[part 2 of 2: packages /PATAC/MSM/ModeAdjust to /PATAC/MSM/PortInterfaces]
AUTOSAR XML (schema 4-0-3)
package /PATAC/MSM/ModeAdjust
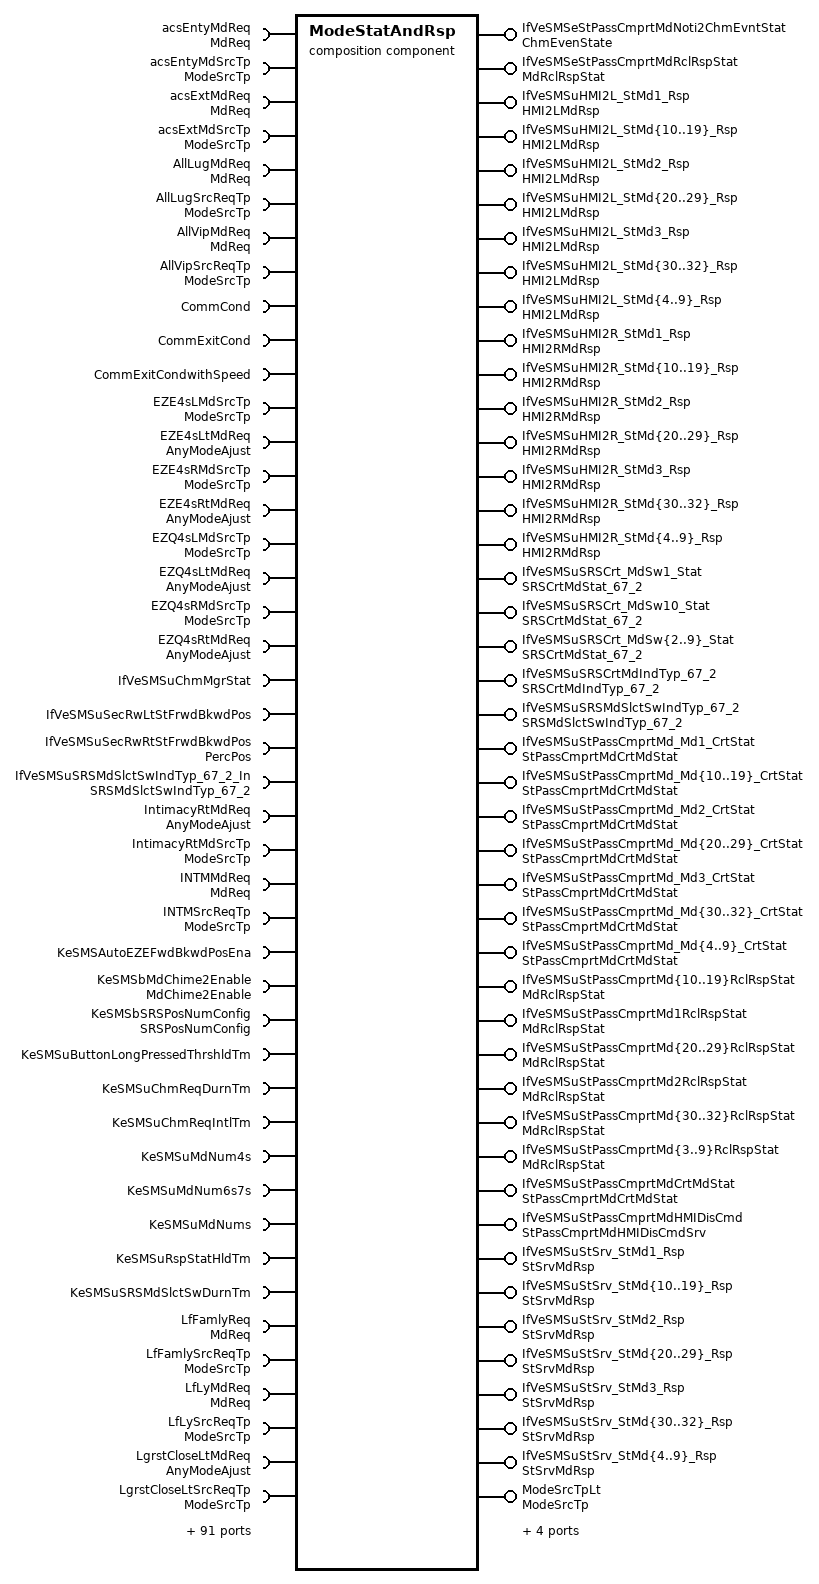
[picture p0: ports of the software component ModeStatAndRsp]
  composition sw component type ModeStatAndRsp
    181 x provide port:
      IfVeSMSeStPassCmprtMdNoti2ChmEvntStat: nonqueued-sender-com-spec=data-element=ChmEvenState/Val, provided-interface=ChmEvenState
      IfVeSMSeStPassCmprtMdRclRspStat: nonqueued-sender-com-spec=data-element=MdRclRspStat/Val, provided-interface=MdRclRspStat
      IfVeSMSuHMI2L_StMd1_Rsp: nonqueued-sender-com-spec=data-element=HMI2LMdRsp/Val, provided-interface=HMI2LMdRsp
      IfVeSMSuHMI2L_StMd{10..19}_Rsp: nonqueued-sender-com-spec=data-element=HMI2LMdRsp/Val, provided-interface=HMI2LMdRsp
      IfVeSMSuHMI2L_StMd2_Rsp: nonqueued-sender-com-spec=data-element=HMI2LMdRsp/Val, provided-interface=HMI2LMdRsp
      IfVeSMSuHMI2L_StMd{20..29}_Rsp: nonqueued-sender-com-spec=data-element=HMI2LMdRsp/Val, provided-interface=HMI2LMdRsp
      IfVeSMSuHMI2L_StMd3_Rsp: nonqueued-sender-com-spec=data-element=HMI2LMdRsp/Val, provided-interface=HMI2LMdRsp
      IfVeSMSuHMI2L_StMd{30..32}_Rsp: nonqueued-sender-com-spec=data-element=HMI2LMdRsp/Val, provided-interface=HMI2LMdRsp
      IfVeSMSuHMI2L_StMd{4..9}_Rsp: nonqueued-sender-com-spec=data-element=HMI2LMdRsp/Val, provided-interface=HMI2LMdRsp
      IfVeSMSuHMI2R_StMd1_Rsp: nonqueued-sender-com-spec=data-element=HMI2RMdRsp/Val, provided-interface=HMI2RMdRsp
      IfVeSMSuHMI2R_StMd{10..19}_Rsp: nonqueued-sender-com-spec=data-element=HMI2RMdRsp/Val, provided-interface=HMI2RMdRsp
      IfVeSMSuHMI2R_StMd2_Rsp: nonqueued-sender-com-spec=data-element=HMI2RMdRsp/Val, provided-interface=HMI2RMdRsp
      IfVeSMSuHMI2R_StMd{20..29}_Rsp: nonqueued-sender-com-spec=data-element=HMI2RMdRsp/Val, provided-interface=HMI2RMdRsp
      IfVeSMSuHMI2R_StMd3_Rsp: nonqueued-sender-com-spec=data-element=HMI2RMdRsp/Val, provided-interface=HMI2RMdRsp
      IfVeSMSuHMI2R_StMd{30..32}_Rsp: nonqueued-sender-com-spec=data-element=HMI2RMdRsp/Val, provided-interface=HMI2RMdRsp
      IfVeSMSuHMI2R_StMd{4..9}_Rsp: nonqueued-sender-com-spec=data-element=HMI2RMdRsp/Val, provided-interface=HMI2RMdRsp
      IfVeSMSuSRSCrt_MdSw1_Stat: nonqueued-sender-com-spec=data-element=SRSCrtMdStat_67_2/Val, provided-interface=SRSCrtMdStat_67_2
      IfVeSMSuSRSCrt_MdSw10_Stat: nonqueued-sender-com-spec=data-element=SRSCrtMdStat_67_2/Val, provided-interface=SRSCrtMdStat_67_2
      IfVeSMSuSRSCrt_MdSw{2..9}_Stat: nonqueued-sender-com-spec=data-element=SRSCrtMdStat_67_2/Val, provided-interface=SRSCrtMdStat_67_2
      IfVeSMSuSRSCrtMdIndTyp_67_2: nonqueued-sender-com-spec=data-element=SRSCrtMdIndTyp_67_2/Val, provided-interface=SRSCrtMdIndTyp_67_2
      IfVeSMSuSRSMdSlctSwIndTyp_67_2: nonqueued-sender-com-spec{data-element=SRSMdSlctSwIndTyp_67_2/Val, init-value=1}, provided-interface=SRSMdSlctSwIndTyp_67_2
      IfVeSMSuStPassCmprtMd_Md1_CrtStat: nonqueued-sender-com-spec=data-element=StPassCmprtMdCrtMdStat/Val, provided-interface=StPassCmprtMdCrtMdStat
      IfVeSMSuStPassCmprtMd_Md{10..19}_CrtStat: nonqueued-sender-com-spec=data-element=StPassCmprtMdCrtMdStat/Val, provided-interface=StPassCmprtMdCrtMdStat
      IfVeSMSuStPassCmprtMd_Md2_CrtStat: nonqueued-sender-com-spec=data-element=StPassCmprtMdCrtMdStat/Val, provided-interface=StPassCmprtMdCrtMdStat
      IfVeSMSuStPassCmprtMd_Md{20..29}_CrtStat: nonqueued-sender-com-spec=data-element=StPassCmprtMdCrtMdStat/Val, provided-interface=StPassCmprtMdCrtMdStat
      IfVeSMSuStPassCmprtMd_Md3_CrtStat: nonqueued-sender-com-spec=data-element=StPassCmprtMdCrtMdStat/Val, provided-interface=StPassCmprtMdCrtMdStat
      IfVeSMSuStPassCmprtMd_Md{30..32}_CrtStat: nonqueued-sender-com-spec=data-element=StPassCmprtMdCrtMdStat/Val, provided-interface=StPassCmprtMdCrtMdStat
      IfVeSMSuStPassCmprtMd_Md{4..9}_CrtStat: nonqueued-sender-com-spec=data-element=StPassCmprtMdCrtMdStat/Val, provided-interface=StPassCmprtMdCrtMdStat
      IfVeSMSuStPassCmprtMd{10..19}RclRspStat: nonqueued-sender-com-spec=data-element=MdRclRspStat/Val, provided-interface=MdRclRspStat
      IfVeSMSuStPassCmprtMd1RclRspStat: nonqueued-sender-com-spec=data-element=MdRclRspStat/Val, provided-interface=MdRclRspStat
      IfVeSMSuStPassCmprtMd{20..29}RclRspStat: nonqueued-sender-com-spec=data-element=MdRclRspStat/Val, provided-interface=MdRclRspStat
      IfVeSMSuStPassCmprtMd2RclRspStat: nonqueued-sender-com-spec=data-element=MdRclRspStat/Val, provided-interface=MdRclRspStat
      IfVeSMSuStPassCmprtMd{30..32}RclRspStat: nonqueued-sender-com-spec=data-element=MdRclRspStat/Val, provided-interface=MdRclRspStat
      IfVeSMSuStPassCmprtMd{3..9}RclRspStat: nonqueued-sender-com-spec=data-element=MdRclRspStat/Val, provided-interface=MdRclRspStat
      IfVeSMSuStPassCmprtMdCrtMdStat: nonqueued-sender-com-spec=data-element=StPassCmprtMdCrtMdStat/Val, provided-interface=StPassCmprtMdCrtMdStat
      IfVeSMSuStPassCmprtMdHMIDisCmd: nonqueued-sender-com-spec=data-element=StPassCmprtMdHMIDisCmdSrv/Val, provided-interface=StPassCmprtMdHMIDisCmdSrv
      IfVeSMSuStSrv_StMd1_Rsp: nonqueued-sender-com-spec=data-element=StSrvMdRsp/Val, provided-interface=StSrvMdRsp
      IfVeSMSuStSrv_StMd{10..19}_Rsp: nonqueued-sender-com-spec=data-element=StSrvMdRsp/Val, provided-interface=StSrvMdRsp
      IfVeSMSuStSrv_StMd2_Rsp: nonqueued-sender-com-spec=data-element=StSrvMdRsp/Val, provided-interface=StSrvMdRsp
      IfVeSMSuStSrv_StMd{20..29}_Rsp: nonqueued-sender-com-spec=data-element=StSrvMdRsp/Val, provided-interface=StSrvMdRsp
      IfVeSMSuStSrv_StMd3_Rsp: nonqueued-sender-com-spec=data-element=StSrvMdRsp/Val, provided-interface=StSrvMdRsp
      IfVeSMSuStSrv_StMd{30..32}_Rsp: nonqueued-sender-com-spec=data-element=StSrvMdRsp/Val, provided-interface=StSrvMdRsp
      IfVeSMSuStSrv_StMd{4..9}_Rsp: nonqueued-sender-com-spec=data-element=StSrvMdRsp/Val, provided-interface=StSrvMdRsp
      ModeSrcTpLt: nonqueued-sender-com-spec=data-element=ModeSrcTp/Val, provided-interface=ModeSrcTp
      modestate32: nonqueued-sender-com-spec=data-element=modestate32/Val, provided-interface=modestate32
      oModeState: nonqueued-sender-com-spec=data-element=ModeState/Val, provided-interface=ModeState
      SRSMdSlctSwStat_67_2: nonqueued-sender-com-spec{data-element=SRSMdSlctSwStat_67_2/Val, init-value=0}, provided-interface=SRSMdSlctSwStat_67_2
      SRSMode: nonqueued-sender-com-spec=data-element=SRSCurMode/Val, provided-interface=SRSCurMode
    135 x require port:
      acsEntyMdReq: nonqueued-receiver-com-spec{data-element=MdReq/Val, filter=data-filter-type=ALWAYS}, required-interface=MdReq
      acsEntyMdSrcTp: nonqueued-receiver-com-spec{data-element=ModeSrcTp/Val, filter=data-filter-type=ALWAYS}, required-interface=ModeSrcTp
      acsExtMdReq: nonqueued-receiver-com-spec{data-element=MdReq/Val, filter=data-filter-type=ALWAYS}, required-interface=MdReq
      acsExtMdSrcTp: nonqueued-receiver-com-spec{data-element=ModeSrcTp/Val, filter=data-filter-type=ALWAYS}, required-interface=ModeSrcTp
      AllLugMdReq: nonqueued-receiver-com-spec{data-element=MdReq/Val, filter=data-filter-type=ALWAYS}, required-interface=MdReq
      AllLugSrcReqTp: nonqueued-receiver-com-spec{data-element=ModeSrcTp/Val, filter=data-filter-type=ALWAYS}, required-interface=ModeSrcTp
      AllVipMdReq: nonqueued-receiver-com-spec{data-element=MdReq/Val, filter=data-filter-type=ALWAYS}, required-interface=MdReq
      AllVipSrcReqTp: nonqueued-receiver-com-spec{data-element=ModeSrcTp/Val, filter=data-filter-type=ALWAYS}, required-interface=ModeSrcTp
      CommCond: nonqueued-receiver-com-spec{data-element=CommCond/Val, filter=data-filter-type=ALWAYS}, required-interface=CommCond
      CommExitCond: nonqueued-receiver-com-spec{data-element=CommExitCond/Val, filter=data-filter-type=ALWAYS}, required-interface=CommExitCond
      CommExitCondwithSpeed: nonqueued-receiver-com-spec{data-element=CommExitCondwithSpeed/Val, filter=data-filter-type=ALWAYS}, required-interface=CommExitCondwithSpeed
      EZE4sLMdSrcTp: nonqueued-receiver-com-spec{data-element=ModeSrcTp/Val, filter=data-filter-type=ALWAYS, init-value=0}, required-interface=ModeSrcTp
      EZE4sLtMdReq: nonqueued-receiver-com-spec{data-element=AnyModeAjust/Val, filter=data-filter-type=ALWAYS, init-value=0}, required-interface=AnyModeAjust
      EZE4sRMdSrcTp: nonqueued-receiver-com-spec{data-element=ModeSrcTp/Val, filter=data-filter-type=ALWAYS, init-value=0}, required-interface=ModeSrcTp
      EZE4sRtMdReq: nonqueued-receiver-com-spec{data-element=AnyModeAjust/Val, filter=data-filter-type=ALWAYS, init-value=0}, required-interface=AnyModeAjust
      EZQ4sLMdSrcTp: nonqueued-receiver-com-spec{data-element=ModeSrcTp/Val, filter=data-filter-type=ALWAYS, init-value=0}, required-interface=ModeSrcTp
      EZQ4sLtMdReq: nonqueued-receiver-com-spec{data-element=AnyModeAjust/Val, filter=data-filter-type=ALWAYS, init-value=0}, required-interface=AnyModeAjust
      EZQ4sRMdSrcTp: nonqueued-receiver-com-spec{data-element=ModeSrcTp/Val, filter=data-filter-type=ALWAYS, init-value=0}, required-interface=ModeSrcTp
      EZQ4sRtMdReq: nonqueued-receiver-com-spec{data-element=AnyModeAjust/Val, filter=data-filter-type=ALWAYS, init-value=0}, required-interface=AnyModeAjust
      IfVeSMSuChmMgrStat: nonqueued-receiver-com-spec{data-element=IfVeSMSuChmMgrStat/Val, filter=data-filter-type=ALWAYS}, required-interface=IfVeSMSuChmMgrStat
      IfVeSMSuSecRwLtStFrwdBkwdPos: nonqueued-receiver-com-spec{data-element=IfVeSMSuSecRwLtStFrwdBkwdPos/Val, filter=data-filter-type=ALWAYS, init-value=0}, required-interface=IfVeSMSuSecRwLtStFrwdBkwdPos
      IfVeSMSuSecRwRtStFrwdBkwdPos: nonqueued-receiver-com-spec{data-element=PercPos/Val, filter=data-filter-type=ALWAYS, init-value=0}, required-interface=PercPos
      IfVeSMSuSRSMdSlctSwIndTyp_67_2_In: nonqueued-receiver-com-spec{data-element=SRSMdSlctSwIndTyp_67_2/Val, filter=data-filter-type=ALWAYS, init-value=1}, required-interface=SRSMdSlctSwIndTyp_67_2
      IntimacyRtMdReq: nonqueued-receiver-com-spec{data-element=AnyModeAjust/Val, filter=data-filter-type=ALWAYS}, required-interface=AnyModeAjust
      IntimacyRtMdSrcTp: nonqueued-receiver-com-spec{data-element=ModeSrcTp/Val, filter=data-filter-type=ALWAYS}, required-interface=ModeSrcTp
      INTMMdReq: nonqueued-receiver-com-spec{data-element=MdReq/Val, filter=data-filter-type=ALWAYS}, required-interface=MdReq
      INTMSrcReqTp: nonqueued-receiver-com-spec{data-element=ModeSrcTp/Val, filter=data-filter-type=ALWAYS}, required-interface=ModeSrcTp
      KeSMSAutoEZEFwdBkwdPosEna: parameter-require-com-spec{init-value=0, parameter=KeSMSAutoEZEFwdBkwdPosEna/Val}, required-interface=KeSMSAutoEZEFwdBkwdPosEna
      KeSMSbMdChime2Enable: parameter-require-com-spec{init-value=0, parameter=MdChime2Enable/Val}, required-interface=MdChime2Enable
      KeSMSbSRSPosNumConfig: parameter-require-com-spec{init-value=4, parameter=SRSPosNumConfig/Val}, required-interface=SRSPosNumConfig
      KeSMSuButtonLongPressedThrshldTm: parameter-require-com-spec{init-value=100, parameter=KeSMSuButtonLongPressedThrshldTm/Val}, required-interface=KeSMSuButtonLongPressedThrshldTm
      KeSMSuChmReqDurnTm: parameter-require-com-spec{init-value=200, parameter=KeSMSuChmReqDurnTm/Val}, required-interface=KeSMSuChmReqDurnTm
      KeSMSuChmReqIntlTm: parameter-require-com-spec{init-value=50, parameter=KeSMSuChmReqIntlTm/Val}, required-interface=KeSMSuChmReqIntlTm
      KeSMSuMdNum4s: parameter-require-com-spec{init-value=16, parameter=KeSMSuMdNum4s/Val}, required-interface=KeSMSuMdNum4s
      KeSMSuMdNum6s7s: parameter-require-com-spec{init-value=14, parameter=KeSMSuMdNum6s7s/Val}, required-interface=KeSMSuMdNum6s7s
      KeSMSuMdNums: parameter-require-com-spec{init-value=26, parameter=KeSMSuMdNums/Val}, required-interface=KeSMSuMdNums
      KeSMSuRspStatHldTm: parameter-require-com-spec{init-value=100, parameter=KeSMSuRspStatHldTm/Val}, required-interface=KeSMSuRspStatHldTm
      KeSMSuSRSMdSlctSwDurnTm: parameter-require-com-spec{init-value=20, parameter=KeSMSuSRSMdSlctSwDurnTm/Val}, required-interface=KeSMSuSRSMdSlctSwDurnTm
      LfFamlyReq: nonqueued-receiver-com-spec{data-element=MdReq/Val, filter=data-filter-type=ALWAYS}, required-interface=MdReq
      LfFamlySrcReqTp: nonqueued-receiver-com-spec{data-element=ModeSrcTp/Val, filter=data-filter-type=ALWAYS}, required-interface=ModeSrcTp
      LfLyMdReq: nonqueued-receiver-com-spec{data-element=MdReq/Val, filter=data-filter-type=ALWAYS}, required-interface=MdReq
      LfLySrcReqTp: nonqueued-receiver-com-spec{data-element=ModeSrcTp/Val, filter=data-filter-type=ALWAYS}, required-interface=ModeSrcTp
      LgrstCloseLtMdReq: nonqueued-receiver-com-spec{data-element=AnyModeAjust/Val, filter=data-filter-type=ALWAYS}, required-interface=AnyModeAjust
      LgrstCloseLtSrcReqTp: nonqueued-receiver-com-spec{data-element=ModeSrcTp/Val, filter=data-filter-type=ALWAYS}, required-interface=ModeSrcTp
      LgrstCloseRtMdReq: nonqueued-receiver-com-spec{data-element=AnyModeAjust/Val, filter=data-filter-type=ALWAYS}, required-interface=AnyModeAjust
      LgrstCloseRtSrcReqTp: nonqueued-receiver-com-spec{data-element=ModeSrcTp/Val, filter=data-filter-type=ALWAYS}, required-interface=ModeSrcTp
      LgrstOpenLtMdReq: nonqueued-receiver-com-spec{data-element=AnyModeAjust/Val, filter=data-filter-type=ALWAYS}, required-interface=AnyModeAjust
      LgrstOpenLtSrcReqTp: nonqueued-receiver-com-spec{data-element=ModeSrcTp/Val, filter=data-filter-type=ALWAYS}, required-interface=ModeSrcTp
      LgrstOpenRtMdReq: nonqueued-receiver-com-spec{data-element=AnyModeAjust/Val, filter=data-filter-type=ALWAYS}, required-interface=AnyModeAjust
      LgrstOpenRtSrcReqTp: nonqueued-receiver-com-spec{data-element=ModeSrcTp/Val, filter=data-filter-type=ALWAYS}, required-interface=ModeSrcTp
      LtLugMdReq: nonqueued-receiver-com-spec{data-element=MdReq/Val, filter=data-filter-type=ALWAYS}, required-interface=MdReq
      LtLugSrcReqTp: nonqueued-receiver-com-spec{data-element=ModeSrcTp/Val, filter=data-filter-type=ALWAYS}, required-interface=ModeSrcTp
      LtRcvyMdReq: nonqueued-receiver-com-spec{data-element=MdReq/Val, filter=data-filter-type=ALWAYS}, required-interface=MdReq
      LtRcvySrcReqTp: nonqueued-receiver-com-spec{data-element=ModeSrcTp/Val, filter=data-filter-type=ALWAYS}, required-interface=ModeSrcTp
      LtVipMdReq: nonqueued-receiver-com-spec{data-element=MdReq/Val, filter=data-filter-type=ALWAYS}, required-interface=MdReq
      LtVipSrcReqTp: nonqueued-receiver-com-spec{data-element=ModeSrcTp/Val, filter=data-filter-type=ALWAYS}, required-interface=ModeSrcTp
      LugMdLtAvl: nonqueued-receiver-com-spec{data-element=ModeAdjustAvailable/Val, filter=data-filter-type=ALWAYS}, required-interface=ModeAdjustAvailable
      LugMdRtAvl: nonqueued-receiver-com-spec{data-element=ModeAdjustAvailable/Val, filter=data-filter-type=ALWAYS}, required-interface=ModeAdjustAvailable
      MdSWIntSrc_R: nonqueued-receiver-com-spec{data-element=MdSWIntSrc_R/Val, filter=data-filter-type=ALWAYS, init-value=0}, required-interface=MdSWIntSrc_R
      MdXX_MdDoneArray: nonqueued-receiver-com-spec{data-element=MdXX_MdDoneArray/Val, filter=data-filter-type=ALWAYS, init-value=32 x 0}, required-interface=MdXX_MdDoneArray
      MdXXIsTargetPosAlready: nonqueued-receiver-com-spec{data-element=IsTargetPos32Bit/Val, filter=data-filter-type=ALWAYS, init-value=0}, required-interface=IsTargetPos32Bit
      MdXXIsTargetPosZone: nonqueued-receiver-com-spec{data-element=IsTargetPos32Bit/Val, filter=data-filter-type=ALWAYS, init-value=0}, required-interface=IsTargetPos32Bit
      PosArray: nonqueued-receiver-com-spec{data-element=PosArray/Val, filter=data-filter-type=ALWAYS, init-value=11 x 0}, required-interface=PosArray
      PwrMdChked: nonqueued-receiver-com-spec{data-element=PowerMode/Val, filter=data-filter-type=ALWAYS}, required-interface=PowerMode
      RtFamlyMdReq: nonqueued-receiver-com-spec{data-element=MdReq/Val, filter=data-filter-type=ALWAYS}, required-interface=MdReq
      RtFamlySrcReqTp: nonqueued-receiver-com-spec{data-element=ModeSrcTp/Val, filter=data-filter-type=ALWAYS}, required-interface=ModeSrcTp
      RtLugMdReq: nonqueued-receiver-com-spec{data-element=MdReq/Val, filter=data-filter-type=ALWAYS}, required-interface=MdReq
      RtLugSrcReqTp: nonqueued-receiver-com-spec{data-element=ModeSrcTp/Val, filter=data-filter-type=ALWAYS}, required-interface=ModeSrcTp
      RtLyMdReq: nonqueued-receiver-com-spec{data-element=MdReq/Val, filter=data-filter-type=ALWAYS}, required-interface=MdReq
      RtLySrcReqTp: nonqueued-receiver-com-spec{data-element=ModeSrcTp/Val, filter=data-filter-type=ALWAYS}, required-interface=ModeSrcTp
      RtRcvyMdReq: nonqueued-receiver-com-spec{data-element=MdReq/Val, filter=data-filter-type=ALWAYS}, required-interface=MdReq
      RtRcvySrcReqTp: nonqueued-receiver-com-spec{data-element=ModeSrcTp/Val, filter=data-filter-type=ALWAYS}, required-interface=ModeSrcTp
      RtVipMdReq: nonqueued-receiver-com-spec{data-element=MdReq/Val, filter=data-filter-type=ALWAYS}, required-interface=MdReq
      RtVipSrcReqTp: nonqueued-receiver-com-spec{data-element=ModeSrcTp/Val, filter=data-filter-type=ALWAYS}, required-interface=ModeSrcTp
      SoftIntAcsEnty: nonqueued-receiver-com-spec{data-element=IntEnable/Val, filter=data-filter-type=ALWAYS}, required-interface=IntEnable
      SoftIntAcsExt: nonqueued-receiver-com-spec{data-element=IntEnable/Val, filter=data-filter-type=ALWAYS}, required-interface=IntEnable
      SoftIntAllLug: nonqueued-receiver-com-spec{data-element=IntEnable/Val, filter=data-filter-type=ALWAYS}, required-interface=IntEnable
      SoftIntAllVip: nonqueued-receiver-com-spec{data-element=IntEnable/Val, filter=data-filter-type=ALWAYS}, required-interface=IntEnable
      SoftIntEZE4sL: nonqueued-receiver-com-spec{data-element=IntEnable/Val, filter=data-filter-type=ALWAYS, init-value=0}, required-interface=IntEnable
      SoftIntEZE4sR: nonqueued-receiver-com-spec{data-element=IntEnable/Val, filter=data-filter-type=ALWAYS, init-value=0}, required-interface=IntEnable
      SoftIntEZQ4sL: nonqueued-receiver-com-spec{data-element=IntEnable/Val, filter=data-filter-type=ALWAYS, init-value=0}, required-interface=IntEnable
      SoftIntEZQ4sR: nonqueued-receiver-com-spec{data-element=IntEnable/Val, filter=data-filter-type=ALWAYS, init-value=0}, required-interface=IntEnable
      SoftIntIntimacyRt: nonqueued-receiver-com-spec{data-element=IntEnable/Val, filter=data-filter-type=ALWAYS}, required-interface=IntEnable
      SoftIntINTM: nonqueued-receiver-com-spec{data-element=IntEnable/Val, filter=data-filter-type=ALWAYS}, required-interface=IntEnable
      SoftIntLfFamly: nonqueued-receiver-com-spec{data-element=IntEnable/Val, filter=data-filter-type=ALWAYS}, required-interface=IntEnable
      SoftIntLfLug: nonqueued-receiver-com-spec{data-element=IntEnable/Val, filter=data-filter-type=ALWAYS}, required-interface=IntEnable
      SoftIntLfLy: nonqueued-receiver-com-spec{data-element=IntEnable/Val, filter=data-filter-type=ALWAYS}, required-interface=IntEnable
      SoftIntLfRcvy: nonqueued-receiver-com-spec{data-element=IntEnable/Val, filter=data-filter-type=ALWAYS}, required-interface=IntEnable
      SoftIntLfVip: nonqueued-receiver-com-spec{data-element=IntEnable/Val, filter=data-filter-type=ALWAYS}, required-interface=IntEnable
      SoftIntLgrstCloseLt: nonqueued-receiver-com-spec{data-element=IntEnable/Val, filter=data-filter-type=ALWAYS}, required-interface=IntEnable
      SoftIntLgrstCloseRt: nonqueued-receiver-com-spec{data-element=IntEnable/Val, filter=data-filter-type=ALWAYS}, required-interface=IntEnable
      SoftIntLgrstOpenLt: nonqueued-receiver-com-spec{data-element=IntEnable/Val, filter=data-filter-type=ALWAYS}, required-interface=IntEnable
      SoftIntLgrstOpenRt: nonqueued-receiver-com-spec{data-element=IntEnable/Val, filter=data-filter-type=ALWAYS}, required-interface=IntEnable
      SoftIntRtFamly: nonqueued-receiver-com-spec{data-element=IntEnable/Val, filter=data-filter-type=ALWAYS}, required-interface=IntEnable
      SoftIntRtLug: nonqueued-receiver-com-spec{data-element=IntEnable/Val, filter=data-filter-type=ALWAYS}, required-interface=IntEnable
      SoftIntRtLy: nonqueued-receiver-com-spec{data-element=IntEnable/Val, filter=data-filter-type=ALWAYS}, required-interface=IntEnable
      SoftIntRtRcvy: nonqueued-receiver-com-spec{data-element=IntEnable/Val, filter=data-filter-type=ALWAYS}, required-interface=IntEnable
      SoftIntRtVip: nonqueued-receiver-com-spec{data-element=IntEnable/Val, filter=data-filter-type=ALWAYS}, required-interface=IntEnable
      SoftIntWelcomeBkwd: nonqueued-receiver-com-spec{data-element=IntEnable/Val, filter=data-filter-type=ALWAYS, init-value=0}, required-interface=IntEnable
      SoftIntWelcomeFwd: nonqueued-receiver-com-spec{data-element=IntEnable/Val, filter=data-filter-type=ALWAYS, init-value=0}, required-interface=IntEnable
      SRSconvertArray: parameter-require-com-spec{init-value=[0, 1, 5, 8, 2, 9, 10, 11, 6, 7, 3, 12, 4, 13, 14, 15, 16, 17, 18, 19, 20, 21, 22, 23, 24, 25, 26, 27, 28, 29, 30, 31], parameter=SRSconvertArray/Val}, required-interface=SRSconvertArray
      SRSMdSlctSwStat_67_2_In: nonqueued-receiver-com-spec{data-element=SRSMdSlctSwStat_67_2/Val, filter=data-filter-type=ALWAYS, init-value=0}, required-interface=SRSMdSlctSwStat_67_2
      StNumFlg: required-interface=StNumFlg
        required-com-specs:
          data-element=Is4s, filter=data-filter-type=ALWAYS, init-value=0
          data-element=Is6s, filter=data-filter-type=ALWAYS, init-value=0
          data-element=Is6s7s, filter=data-filter-type=ALWAYS, init-value=0
          data-element=Is7s, filter=data-filter-type=ALWAYS, init-value=0
      SwIntAcsEnty: nonqueued-receiver-com-spec{data-element=IntEnable/Val, filter=data-filter-type=ALWAYS}, required-interface=IntEnable
      SwIntAcsExt: nonqueued-receiver-com-spec{data-element=IntEnable/Val, filter=data-filter-type=ALWAYS}, required-interface=IntEnable
      SwIntAllLug: nonqueued-receiver-com-spec{data-element=IntEnable/Val, filter=data-filter-type=ALWAYS}, required-interface=IntEnable
      SwIntAllVip: nonqueued-receiver-com-spec{data-element=IntEnable/Val, filter=data-filter-type=ALWAYS}, required-interface=IntEnable
      SwIntEZE4sL: nonqueued-receiver-com-spec{data-element=IntEnable/Val, filter=data-filter-type=ALWAYS, init-value=0}, required-interface=IntEnable
      SwIntEZE4sR: nonqueued-receiver-com-spec{data-element=IntEnable/Val, filter=data-filter-type=ALWAYS, init-value=0}, required-interface=IntEnable
      SwIntEZQ4sL: nonqueued-receiver-com-spec{data-element=IntEnable/Val, filter=data-filter-type=ALWAYS, init-value=0}, required-interface=IntEnable
      SwIntEZQ4sR: nonqueued-receiver-com-spec{data-element=IntEnable/Val, filter=data-filter-type=ALWAYS, init-value=0}, required-interface=IntEnable
      SwIntIntimacyRt: nonqueued-receiver-com-spec{data-element=IntEnable/Val, filter=data-filter-type=ALWAYS}, required-interface=IntEnable
      SwIntINTM: nonqueued-receiver-com-spec{data-element=IntEnable/Val, filter=data-filter-type=ALWAYS}, required-interface=IntEnable
      SwIntLfFamly: nonqueued-receiver-com-spec{data-element=IntEnable/Val, filter=data-filter-type=ALWAYS}, required-interface=IntEnable
      SwIntLfLug: nonqueued-receiver-com-spec{data-element=IntEnable/Val, filter=data-filter-type=ALWAYS}, required-interface=IntEnable
      SwIntLfLy: nonqueued-receiver-com-spec{data-element=IntEnable/Val, filter=data-filter-type=ALWAYS}, required-interface=IntEnable
      SwIntLfRcvy: nonqueued-receiver-com-spec{data-element=IntEnable/Val, filter=data-filter-type=ALWAYS}, required-interface=IntEnable
      SwIntLfVip: nonqueued-receiver-com-spec{data-element=IntEnable/Val, filter=data-filter-type=ALWAYS}, required-interface=IntEnable
      SwIntLgrstCloseLt: nonqueued-receiver-com-spec{data-element=IntEnable/Val, filter=data-filter-type=ALWAYS}, required-interface=IntEnable
      SwIntLgrstCloseRt: nonqueued-receiver-com-spec{data-element=IntEnable/Val, filter=data-filter-type=ALWAYS}, required-interface=IntEnable
      SwIntLgrstOpenLt: nonqueued-receiver-com-spec{data-element=IntEnable/Val, filter=data-filter-type=ALWAYS}, required-interface=IntEnable
      SwIntLgrstOpenRt: nonqueued-receiver-com-spec{data-element=IntEnable/Val, filter=data-filter-type=ALWAYS}, required-interface=IntEnable
      SwIntRtFamly: nonqueued-receiver-com-spec{data-element=IntEnable/Val, filter=data-filter-type=ALWAYS}, required-interface=IntEnable
      SwIntRtLug: nonqueued-receiver-com-spec{data-element=IntEnable/Val, filter=data-filter-type=ALWAYS}, required-interface=IntEnable
      SwIntRtLy: nonqueued-receiver-com-spec{data-element=IntEnable/Val, filter=data-filter-type=ALWAYS}, required-interface=IntEnable
      SwIntRtRcvy: nonqueued-receiver-com-spec{data-element=IntEnable/Val, filter=data-filter-type=ALWAYS}, required-interface=IntEnable
      SwIntRtVip: nonqueued-receiver-com-spec{data-element=IntEnable/Val, filter=data-filter-type=ALWAYS}, required-interface=IntEnable
      SwIntWelcomeBkwd: nonqueued-receiver-com-spec{data-element=IntEnable/Val, filter=data-filter-type=ALWAYS, init-value=0}, required-interface=IntEnable
      SwIntWelcomeFwd: nonqueued-receiver-com-spec{data-element=IntEnable/Val, filter=data-filter-type=ALWAYS, init-value=0}, required-interface=IntEnable
      VipMdLtAvl: nonqueued-receiver-com-spec{data-element=ModeAdjustAvailable/Val, filter=data-filter-type=ALWAYS}, required-interface=ModeAdjustAvailable
      VipMdRtAvl: nonqueued-receiver-com-spec{data-element=ModeAdjustAvailable/Val, filter=data-filter-type=ALWAYS}, required-interface=ModeAdjustAvailable
      WelcomeBkwdMdReq: nonqueued-receiver-com-spec{data-element=AnyModeAjust/Val, filter=data-filter-type=ALWAYS, init-value=0}, required-interface=AnyModeAjust
      WelcomeBkwdMdSrcTp: nonqueued-receiver-com-spec{data-element=ModeSrcTp/Val, filter=data-filter-type=ALWAYS, init-value=0}, required-interface=ModeSrcTp
      WelcomeFwdMdReq: nonqueued-receiver-com-spec{data-element=AnyModeAjust/Val, filter=data-filter-type=ALWAYS, init-value=0}, required-interface=AnyModeAjust
      WelcomeFwdMdSrcTp: nonqueued-receiver-com-spec{data-element=ModeSrcTp/Val, filter=data-filter-type=ALWAYS, init-value=0}, required-interface=ModeSrcTp
    component ModeRsp: type=ModeRsp
    component ModeStatAndRspCaller: type=ModeStatAndRspCaller
    component ModeStatCtrl: type=ModeStatCtrl
    connect ModeRsp.ModeRsp -> ModeStatAndRspCaller.ModeRsp
    connect ModeStatCtrl.IsStBsy32Bit -> ModeRsp.IsStBsy32Bit
    connect ModeStatCtrl.MdXX_QuitArray -> ModeRsp.MdXX_QuitArray
    connect ModeStatCtrl.MdXX_SrcReqTpArray -> ModeRsp.MdXX_SrcReqTpArray
    connect ModeStatCtrl.modestate32 -> ModeRsp.modestate32
    connect ModeStatCtrl.ModeStateCtrl -> ModeStatAndRspCaller.ModeStateCtrl
    delegate ModeStatCtrl.acsEntyMdReq <-> outer port ModeStatAndRsp/acsEntyMdReq
    delegate ModeStatCtrl.acsEntyMdSrcTp <-> outer port ModeStatAndRsp/acsEntyMdSrcTp
    delegate ModeStatCtrl.acsExtMdReq <-> outer port ModeStatAndRsp/acsExtMdReq
    delegate ModeStatCtrl.acsExtMdSrcTp <-> outer port ModeStatAndRsp/acsExtMdSrcTp
    delegate ModeStatCtrl.AllLugMdReq <-> outer port ModeStatAndRsp/AllLugMdReq
    delegate ModeStatCtrl.AllLugSrcReqTp <-> outer port ModeStatAndRsp/AllLugSrcReqTp
    delegate ModeStatCtrl.AllVipMdReq <-> outer port ModeStatAndRsp/AllVipMdReq
    delegate ModeStatCtrl.AllVipSrcReqTp <-> outer port ModeStatAndRsp/AllVipSrcReqTp
    delegate ModeStatCtrl.CommCond <-> outer port ModeStatAndRsp/CommCond
    delegate ModeStatCtrl.CommExitCond <-> outer port ModeStatAndRsp/CommExitCond
    delegate ModeStatCtrl.CommExitCondwithSpeed <-> outer port ModeStatAndRsp/CommExitCondwithSpeed
    delegate ModeStatCtrl.EZE4sLMdSrcTp <-> outer port ModeStatAndRsp/EZE4sLMdSrcTp
    delegate ModeStatCtrl.EZE4sLtMdReq <-> outer port ModeStatAndRsp/EZE4sLtMdReq
    delegate ModeStatCtrl.EZE4sRMdSrcTp <-> outer port ModeStatAndRsp/EZE4sRMdSrcTp
    delegate ModeStatCtrl.EZE4sRtMdReq <-> outer port ModeStatAndRsp/EZE4sRtMdReq
    delegate ModeStatCtrl.EZQ4sLMdSrcTp <-> outer port ModeStatAndRsp/EZQ4sLMdSrcTp
    delegate ModeStatCtrl.EZQ4sLtMdReq <-> outer port ModeStatAndRsp/EZQ4sLtMdReq
    delegate ModeStatCtrl.EZQ4sRMdSrcTp <-> outer port ModeStatAndRsp/EZQ4sRMdSrcTp
    delegate ModeStatCtrl.EZQ4sRtMdReq <-> outer port ModeStatAndRsp/EZQ4sRtMdReq
    delegate ModeRsp.IfVeSMSeStPassCmprtMdNoti2ChmEvntStat <-> outer port ModeStatAndRsp/IfVeSMSeStPassCmprtMdNoti2ChmEvntStat
    delegate ModeRsp.IfVeSMStPassCmprtMd_RfCtrl_Sw_RclRspStat <-> outer port IfVeSMSeStPassCmprtMdRclRspStat
    delegate ModeRsp.IfVeSMSuChmMgrStat <-> outer port ModeStatAndRsp/IfVeSMSuChmMgrStat
    delegate ModeRsp.IfVeSMSuHMI2L_StMd1_Rsp <-> outer port ModeStatAndRsp/IfVeSMSuHMI2L_StMd1_Rsp
    delegate ModeRsp.IfVeSMSuHMI2L_StMd{10..19}_Rsp <-> outer port ModeStatAndRsp/IfVeSMSuHMI2L_StMd{10..19}_Rsp
    delegate ModeRsp.IfVeSMSuHMI2L_StMd2_Rsp <-> outer port ModeStatAndRsp/IfVeSMSuHMI2L_StMd2_Rsp
    delegate ModeRsp.IfVeSMSuHMI2L_StMd{20..29}_Rsp <-> outer port ModeStatAndRsp/IfVeSMSuHMI2L_StMd{20..29}_Rsp
    delegate ModeRsp.IfVeSMSuHMI2L_StMd3_Rsp <-> outer port ModeStatAndRsp/IfVeSMSuHMI2L_StMd3_Rsp
    delegate ModeRsp.IfVeSMSuHMI2L_StMd{30..32}_Rsp <-> outer port ModeStatAndRsp/IfVeSMSuHMI2L_StMd{30..32}_Rsp
    delegate ModeRsp.IfVeSMSuHMI2L_StMd{4..9}_Rsp <-> outer port ModeStatAndRsp/IfVeSMSuHMI2L_StMd{4..9}_Rsp
    delegate ModeRsp.IfVeSMSuHMI2R_StMd1_Rsp <-> outer port ModeStatAndRsp/IfVeSMSuHMI2R_StMd1_Rsp
    delegate ModeRsp.IfVeSMSuHMI2R_StMd{10..19}_Rsp <-> outer port ModeStatAndRsp/IfVeSMSuHMI2R_StMd{10..19}_Rsp
    delegate ModeRsp.IfVeSMSuHMI2R_StMd2_Rsp <-> outer port ModeStatAndRsp/IfVeSMSuHMI2R_StMd2_Rsp
    delegate ModeRsp.IfVeSMSuHMI2R_StMd{20..29}_Rsp <-> outer port ModeStatAndRsp/IfVeSMSuHMI2R_StMd{20..29}_Rsp
    delegate ModeRsp.IfVeSMSuHMI2R_StMd3_Rsp <-> outer port ModeStatAndRsp/IfVeSMSuHMI2R_StMd3_Rsp
    delegate ModeRsp.IfVeSMSuHMI2R_StMd{30..32}_Rsp <-> outer port ModeStatAndRsp/IfVeSMSuHMI2R_StMd{30..32}_Rsp
    delegate ModeRsp.IfVeSMSuHMI2R_StMd{4..9}_Rsp <-> outer port ModeStatAndRsp/IfVeSMSuHMI2R_StMd{4..9}_Rsp
    delegate ModeStatCtrl.IfVeSMSuSecRwLtStFrwdBkwdPos <-> outer port ModeStatAndRsp/IfVeSMSuSecRwLtStFrwdBkwdPos
    delegate ModeStatCtrl.IfVeSMSuSecRwRtStFrwdBkwdPos <-> outer port ModeStatAndRsp/IfVeSMSuSecRwRtStFrwdBkwdPos
    delegate ModeRsp.IfVeSMSuSRSCrt_MdSw1_Stat <-> outer port ModeStatAndRsp/IfVeSMSuSRSCrt_MdSw1_Stat
    delegate ModeRsp.IfVeSMSuSRSCrt_MdSw10_Stat <-> outer port ModeStatAndRsp/IfVeSMSuSRSCrt_MdSw10_Stat
    delegate ModeRsp.IfVeSMSuSRSCrt_MdSw{2..9}_Stat <-> outer port ModeStatAndRsp/IfVeSMSuSRSCrt_MdSw{2..9}_Stat
    delegate ModeRsp.IfVeSMSuSRSCrtMdIndTyp_67_2 <-> outer port ModeStatAndRsp/IfVeSMSuSRSCrtMdIndTyp_67_2
    delegate ModeRsp.IfVeSMSuSRSMdSlctSwIndTyp_67_2 <-> outer port ModeStatAndRsp/IfVeSMSuSRSMdSlctSwIndTyp_67_2
    delegate ModeRsp.IfVeSMSuSRSMdSlctSwIndTyp_67_2_In <-> outer port ModeStatAndRsp/IfVeSMSuSRSMdSlctSwIndTyp_67_2_In
    delegate ModeRsp.IfVeSMSuStPassCmprtMd_Md1_CrtStat <-> outer port ModeStatAndRsp/IfVeSMSuStPassCmprtMd_Md1_CrtStat
    delegate ModeRsp.IfVeSMSuStPassCmprtMd_Md{10..19}_CrtStat <-> outer port ModeStatAndRsp/IfVeSMSuStPassCmprtMd_Md{10..19}_CrtStat
    delegate ModeRsp.IfVeSMSuStPassCmprtMd_Md2_CrtStat <-> outer port ModeStatAndRsp/IfVeSMSuStPassCmprtMd_Md2_CrtStat
    delegate ModeRsp.IfVeSMSuStPassCmprtMd_Md{20..29}_CrtStat <-> outer port ModeStatAndRsp/IfVeSMSuStPassCmprtMd_Md{20..29}_CrtStat
    delegate ModeRsp.IfVeSMSuStPassCmprtMd_Md3_CrtStat <-> outer port ModeStatAndRsp/IfVeSMSuStPassCmprtMd_Md3_CrtStat
    delegate ModeRsp.IfVeSMSuStPassCmprtMd_Md{30..32}_CrtStat <-> outer port ModeStatAndRsp/IfVeSMSuStPassCmprtMd_Md{30..32}_CrtStat
    delegate ModeRsp.IfVeSMSuStPassCmprtMd_Md{4..9}_CrtStat <-> outer port ModeStatAndRsp/IfVeSMSuStPassCmprtMd_Md{4..9}_CrtStat
    delegate ModeRsp.IfVeSMSuStPassCmprtMd{10..19}RclRspStat <-> outer port ModeStatAndRsp/IfVeSMSuStPassCmprtMd{10..19}RclRspStat
    delegate ModeRsp.IfVeSMSuStPassCmprtMd1RclRspStat <-> outer port ModeStatAndRsp/IfVeSMSuStPassCmprtMd1RclRspStat
    delegate ModeRsp.IfVeSMSuStPassCmprtMd{20..29}RclRspStat <-> outer port ModeStatAndRsp/IfVeSMSuStPassCmprtMd{20..29}RclRspStat
    delegate ModeRsp.IfVeSMSuStPassCmprtMd2RclRspStat <-> outer port ModeStatAndRsp/IfVeSMSuStPassCmprtMd2RclRspStat
    delegate ModeRsp.IfVeSMSuStPassCmprtMd{30..32}RclRspStat <-> outer port ModeStatAndRsp/IfVeSMSuStPassCmprtMd{30..32}RclRspStat
    delegate ModeRsp.IfVeSMSuStPassCmprtMd{3..9}RclRspStat <-> outer port ModeStatAndRsp/IfVeSMSuStPassCmprtMd{3..9}RclRspStat
    delegate ModeRsp.IfVeSMSuStPassCmprtMdCrtMdStat <-> outer port ModeStatAndRsp/IfVeSMSuStPassCmprtMdCrtMdStat
    delegate ModeRsp.IfVeSMSuStPassCmprtMdHMIDisCmd <-> outer port ModeStatAndRsp/IfVeSMSuStPassCmprtMdHMIDisCmd
    delegate ModeRsp.IfVeSMSuStSrv_StMd1_Rsp <-> outer port ModeStatAndRsp/IfVeSMSuStSrv_StMd1_Rsp
    delegate ModeRsp.IfVeSMSuStSrv_StMd{10..19}_Rsp <-> outer port ModeStatAndRsp/IfVeSMSuStSrv_StMd{10..19}_Rsp
    delegate ModeRsp.IfVeSMSuStSrv_StMd2_Rsp <-> outer port ModeStatAndRsp/IfVeSMSuStSrv_StMd2_Rsp
    delegate ModeRsp.IfVeSMSuStSrv_StMd{20..29}_Rsp <-> outer port ModeStatAndRsp/IfVeSMSuStSrv_StMd{20..29}_Rsp
    delegate ModeRsp.IfVeSMSuStSrv_StMd3_Rsp <-> outer port ModeStatAndRsp/IfVeSMSuStSrv_StMd3_Rsp
    delegate ModeRsp.IfVeSMSuStSrv_StMd{30..32}_Rsp <-> outer port ModeStatAndRsp/IfVeSMSuStSrv_StMd{30..32}_Rsp
    delegate ModeRsp.IfVeSMSuStSrv_StMd{4..9}_Rsp <-> outer port ModeStatAndRsp/IfVeSMSuStSrv_StMd{4..9}_Rsp
    delegate ModeStatCtrl.IntimacyRtMdReq <-> outer port ModeStatAndRsp/IntimacyRtMdReq
    delegate ModeStatCtrl.IntimacyRtMdSrcTp <-> outer port ModeStatAndRsp/IntimacyRtMdSrcTp
    delegate ModeStatCtrl.INTMMdReq <-> outer port ModeStatAndRsp/INTMMdReq
    delegate ModeStatCtrl.INTMSrcReqTp <-> outer port ModeStatAndRsp/INTMSrcReqTp
    delegate ModeStatCtrl.KeSMSAutoEZEFwdBkwdPosEna <-> outer port ModeStatAndRsp/KeSMSAutoEZEFwdBkwdPosEna
    delegate ModeRsp.KeSMSbMdChime2Enable <-> outer port ModeStatAndRsp/KeSMSbMdChime2Enable
    delegate ModeRsp.KeSMSbSRSPosNumConfig <-> outer port ModeStatAndRsp/KeSMSbSRSPosNumConfig
    delegate ModeStatCtrl.KeSMSuButtonLongPressedThrshldTm <-> outer port ModeStatAndRsp/KeSMSuButtonLongPressedThrshldTm
    delegate ModeRsp.KeSMSuChmReqDurnTm <-> outer port ModeStatAndRsp/KeSMSuChmReqDurnTm
    delegate ModeRsp.KeSMSuChmReqIntlTm <-> outer port ModeStatAndRsp/KeSMSuChmReqIntlTm
    delegate ModeStatCtrl.KeSMSuMdNum4s <-> outer port ModeStatAndRsp/KeSMSuMdNum4s
    delegate ModeStatCtrl.KeSMSuMdNum6s7s <-> outer port ModeStatAndRsp/KeSMSuMdNum6s7s
    delegate ModeStatCtrl.KeSMSuMdNums <-> outer port ModeStatAndRsp/KeSMSuMdNums
    delegate ModeRsp.KeSMSuMdNums <-> outer port ModeStatAndRsp/KeSMSuMdNums
    delegate ModeRsp.KeSMSuRspStatHldTm <-> outer port ModeStatAndRsp/KeSMSuRspStatHldTm
    delegate ModeRsp.KeSMSuSRSMdSlctSwDurnTm <-> outer port ModeStatAndRsp/KeSMSuSRSMdSlctSwDurnTm
    delegate ModeStatCtrl.LfFamlyReq <-> outer port ModeStatAndRsp/LfFamlyReq
    delegate ModeStatCtrl.LfFamlySrcReqTp <-> outer port ModeStatAndRsp/LfFamlySrcReqTp
    delegate ModeStatCtrl.LfLyMdReq <-> outer port ModeStatAndRsp/LfLyMdReq
    delegate ModeStatCtrl.LfLySrcReqTp <-> outer port ModeStatAndRsp/LfLySrcReqTp
    delegate ModeStatCtrl.LgrstCloseLtMdReq <-> outer port ModeStatAndRsp/LgrstCloseLtMdReq
    delegate ModeStatCtrl.LgrstCloseLtSrcReqTp <-> outer port ModeStatAndRsp/LgrstCloseLtSrcReqTp
    delegate ModeStatCtrl.LgrstCloseRtMdReq <-> outer port ModeStatAndRsp/LgrstCloseRtMdReq
    delegate ModeStatCtrl.LgrstCloseRtSrcReqTp <-> outer port ModeStatAndRsp/LgrstCloseRtSrcReqTp
    delegate ModeStatCtrl.LgrstOpenLtMdReq <-> outer port ModeStatAndRsp/LgrstOpenLtMdReq
    delegate ModeStatCtrl.LgrstOpenLtSrcReqTp <-> outer port ModeStatAndRsp/LgrstOpenLtSrcReqTp
    delegate ModeStatCtrl.LgrstOpenRtMdReq <-> outer port ModeStatAndRsp/LgrstOpenRtMdReq
    delegate ModeStatCtrl.LgrstOpenRtSrcReqTp <-> outer port ModeStatAndRsp/LgrstOpenRtSrcReqTp
    delegate ModeStatCtrl.LtLugMdReq <-> outer port ModeStatAndRsp/LtLugMdReq
    delegate ModeStatCtrl.LtLugSrcReqTp <-> outer port ModeStatAndRsp/LtLugSrcReqTp
    delegate ModeStatCtrl.LtRcvyMdReq <-> outer port ModeStatAndRsp/LtRcvyMdReq
    delegate ModeStatCtrl.LtRcvySrcReqTp <-> outer port ModeStatAndRsp/LtRcvySrcReqTp
    delegate ModeStatCtrl.LtVipMdReq <-> outer port ModeStatAndRsp/LtVipMdReq
    delegate ModeStatCtrl.LtVipSrcReqTp <-> outer port ModeStatAndRsp/LtVipSrcReqTp
    delegate ModeStatCtrl.LugMdLtAvl <-> outer port ModeStatAndRsp/LugMdLtAvl
    delegate ModeStatCtrl.LugMdRtAvl <-> outer port ModeStatAndRsp/LugMdRtAvl
    delegate ModeStatCtrl.MdSWIntSrc_R <-> outer port ModeStatAndRsp/MdSWIntSrc_R
    delegate ModeStatCtrl.MdXX_MdDoneArray <-> outer port ModeStatAndRsp/MdXX_MdDoneArray
    delegate ModeRsp.MdXXIsTargetPosAlready <-> outer port ModeStatAndRsp/MdXXIsTargetPosAlready
    delegate ModeRsp.MdXXIsTargetPosZone <-> outer port ModeStatAndRsp/MdXXIsTargetPosZone
    delegate ModeRsp.ModeSrcTpLt <-> outer port ModeStatAndRsp/ModeSrcTpLt
    delegate ModeStatCtrl.modestate32 <-> outer port ModeStatAndRsp/modestate32
    delegate ModeRsp.oModeState <-> outer port ModeStatAndRsp/oModeState
    delegate ModeRsp.PosArray <-> outer port ModeStatAndRsp/PosArray
    delegate ModeRsp.PwrMdChked <-> outer port ModeStatAndRsp/PwrMdChked
    delegate ModeStatCtrl.RtFamlyMdReq <-> outer port ModeStatAndRsp/RtFamlyMdReq
    delegate ModeStatCtrl.RtFamlySrcReqTp <-> outer port ModeStatAndRsp/RtFamlySrcReqTp
    delegate ModeStatCtrl.RtLugMdReq <-> outer port ModeStatAndRsp/RtLugMdReq
    delegate ModeStatCtrl.RtLugSrcReqTp <-> outer port ModeStatAndRsp/RtLugSrcReqTp
    delegate ModeStatCtrl.RtLyMdReq <-> outer port ModeStatAndRsp/RtLyMdReq
    delegate ModeStatCtrl.RtLySrcReqTp <-> outer port ModeStatAndRsp/RtLySrcReqTp
    delegate ModeStatCtrl.RtRcvyMdReq <-> outer port ModeStatAndRsp/RtRcvyMdReq
    delegate ModeStatCtrl.RtRcvySrcReqTp <-> outer port ModeStatAndRsp/RtRcvySrcReqTp
    delegate ModeStatCtrl.RtVipMdReq <-> outer port ModeStatAndRsp/RtVipMdReq
    delegate ModeStatCtrl.RtVipSrcReqTp <-> outer port ModeStatAndRsp/RtVipSrcReqTp
    delegate ModeStatCtrl.SoftIntAcsEnty <-> outer port ModeStatAndRsp/SoftIntAcsEnty
    delegate ModeStatCtrl.SoftIntAcsExt <-> outer port ModeStatAndRsp/SoftIntAcsExt
    delegate ModeStatCtrl.SoftIntAllLug <-> outer port ModeStatAndRsp/SoftIntAllLug
    delegate ModeStatCtrl.SoftIntAllVip <-> outer port ModeStatAndRsp/SoftIntAllVip
    delegate ModeStatCtrl.SoftIntEZE4sL <-> outer port ModeStatAndRsp/SoftIntEZE4sL
    delegate ModeStatCtrl.SoftIntEZE4sR <-> outer port ModeStatAndRsp/SoftIntEZE4sR
    delegate ModeStatCtrl.SoftIntEZQ4sL <-> outer port ModeStatAndRsp/SoftIntEZQ4sL
    delegate ModeStatCtrl.SoftIntEZQ4sR <-> outer port ModeStatAndRsp/SoftIntEZQ4sR
    delegate ModeStatCtrl.SoftIntIntimacyRt <-> outer port ModeStatAndRsp/SoftIntIntimacyRt
    delegate ModeStatCtrl.SoftIntINTM <-> outer port ModeStatAndRsp/SoftIntINTM
    delegate ModeStatCtrl.SoftIntLfFamly <-> outer port ModeStatAndRsp/SoftIntLfFamly
    delegate ModeStatCtrl.SoftIntLfLug <-> outer port ModeStatAndRsp/SoftIntLfLug
    delegate ModeStatCtrl.SoftIntLfLy <-> outer port ModeStatAndRsp/SoftIntLfLy
    delegate ModeStatCtrl.SoftIntLfRcvy <-> outer port ModeStatAndRsp/SoftIntLfRcvy
    delegate ModeStatCtrl.SoftIntLfVip <-> outer port ModeStatAndRsp/SoftIntLfVip
    delegate ModeStatCtrl.SoftIntLgrstCloseLt <-> outer port ModeStatAndRsp/SoftIntLgrstCloseLt
    delegate ModeStatCtrl.SoftIntLgrstCloseRt <-> outer port ModeStatAndRsp/SoftIntLgrstCloseRt
    delegate ModeStatCtrl.SoftIntLgrstOpenLt <-> outer port ModeStatAndRsp/SoftIntLgrstOpenLt
    delegate ModeStatCtrl.SoftIntLgrstOpenRt <-> outer port ModeStatAndRsp/SoftIntLgrstOpenRt
    delegate ModeStatCtrl.SoftIntRtFamly <-> outer port ModeStatAndRsp/SoftIntRtFamly
    delegate ModeStatCtrl.SoftIntRtLug <-> outer port ModeStatAndRsp/SoftIntRtLug
    delegate ModeStatCtrl.SoftIntRtLy <-> outer port ModeStatAndRsp/SoftIntRtLy
    delegate ModeStatCtrl.SoftIntRtRcvy <-> outer port ModeStatAndRsp/SoftIntRtRcvy
    delegate ModeStatCtrl.SoftIntRtVip <-> outer port ModeStatAndRsp/SoftIntRtVip
    delegate ModeStatCtrl.SoftIntWelcomeBkwd <-> outer port ModeStatAndRsp/SoftIntWelcomeBkwd
    delegate ModeStatCtrl.SoftIntWelcomeFwd <-> outer port ModeStatAndRsp/SoftIntWelcomeFwd
    delegate ModeRsp.SRSconvertArray <-> outer port ModeStatAndRsp/SRSconvertArray
    delegate ModeRsp.SRSMdSlctSwStat_67_2 <-> outer port ModeStatAndRsp/SRSMdSlctSwStat_67_2
    delegate ModeRsp.SRSMdSlctSwStat_67_2_In <-> outer port ModeStatAndRsp/SRSMdSlctSwStat_67_2_In
    delegate ModeRsp.SRSMode <-> outer port ModeStatAndRsp/SRSMode
    delegate ModeStatCtrl.StNumFlg <-> outer port ModeStatAndRsp/StNumFlg
    delegate ModeStatCtrl.SwIntAcsEnty <-> outer port ModeStatAndRsp/SwIntAcsEnty
    delegate ModeStatCtrl.SwIntAcsExt <-> outer port ModeStatAndRsp/SwIntAcsExt
    delegate ModeStatCtrl.SwIntAllLug <-> outer port ModeStatAndRsp/SwIntAllLug
    delegate ModeStatCtrl.SwIntAllVip <-> outer port ModeStatAndRsp/SwIntAllVip
    delegate ModeStatCtrl.SwIntEZE4sL <-> outer port ModeStatAndRsp/SwIntEZE4sL
    delegate ModeStatCtrl.SwIntEZE4sR <-> outer port ModeStatAndRsp/SwIntEZE4sR
    delegate ModeStatCtrl.SwIntEZQ4sL <-> outer port ModeStatAndRsp/SwIntEZQ4sL
    delegate ModeStatCtrl.SwIntEZQ4sR <-> outer port ModeStatAndRsp/SwIntEZQ4sR
    delegate ModeStatCtrl.SwIntIntimacyRt <-> outer port ModeStatAndRsp/SwIntIntimacyRt
    delegate ModeStatCtrl.SwIntINTM <-> outer port ModeStatAndRsp/SwIntINTM
    delegate ModeStatCtrl.SwIntLfFamly <-> outer port ModeStatAndRsp/SwIntLfFamly
    delegate ModeStatCtrl.SwIntLfLug <-> outer port ModeStatAndRsp/SwIntLfLug
    delegate ModeStatCtrl.SwIntLfLy <-> outer port ModeStatAndRsp/SwIntLfLy
    delegate ModeStatCtrl.SwIntLfRcvy <-> outer port ModeStatAndRsp/SwIntLfRcvy
    delegate ModeStatCtrl.SwIntLfVip <-> outer port ModeStatAndRsp/SwIntLfVip
    delegate ModeStatCtrl.SwIntLgrstCloseLt <-> outer port ModeStatAndRsp/SwIntLgrstCloseLt
    delegate ModeStatCtrl.SwIntLgrstCloseRt <-> outer port ModeStatAndRsp/SwIntLgrstCloseRt
    delegate ModeStatCtrl.SwIntLgrstOpenLt <-> outer port ModeStatAndRsp/SwIntLgrstOpenLt
    delegate ModeStatCtrl.SwIntLgrstOpenRt <-> outer port ModeStatAndRsp/SwIntLgrstOpenRt
    delegate ModeStatCtrl.SwIntRtFamly <-> outer port ModeStatAndRsp/SwIntRtFamly
    delegate ModeStatCtrl.SwIntRtLug <-> outer port ModeStatAndRsp/SwIntRtLug
    delegate ModeStatCtrl.SwIntRtLy <-> outer port ModeStatAndRsp/SwIntRtLy
    delegate ModeStatCtrl.SwIntRtRcvy <-> outer port ModeStatAndRsp/SwIntRtRcvy
    delegate ModeStatCtrl.SwIntRtVip <-> outer port ModeStatAndRsp/SwIntRtVip
    delegate ModeStatCtrl.SwIntWelcomeBkwd <-> outer port ModeStatAndRsp/SwIntWelcomeBkwd
    delegate ModeStatCtrl.SwIntWelcomeFwd <-> outer port ModeStatAndRsp/SwIntWelcomeFwd
    delegate ModeStatCtrl.VipMdLtAvl <-> outer port ModeStatAndRsp/VipMdLtAvl
    delegate ModeStatCtrl.VipMdRtAvl <-> outer port ModeStatAndRsp/VipMdRtAvl
    delegate ModeStatCtrl.WelcomeBkwdMdReq <-> outer port ModeStatAndRsp/WelcomeBkwdMdReq
    delegate ModeStatCtrl.WelcomeBkwdMdSrcTp <-> outer port ModeStatAndRsp/WelcomeBkwdMdSrcTp
    delegate ModeStatCtrl.WelcomeFwdMdReq <-> outer port ModeStatAndRsp/WelcomeFwdMdReq
    delegate ModeStatCtrl.WelcomeFwdMdSrcTp <-> outer port ModeStatAndRsp/WelcomeFwdMdSrcTp
package /PATAC/MSM/ModeAdjust/CalPortInterface
  10 x parameter interface:
    KeSMSAutoEZEFwdBkwdPosEna
      parameter data prototype Val: sw-calibration-access=READ-WRITE, type=UInt16
    KeSMSuButtonLongPressedThrshldTm
      parameter data prototype Val: sw-calibration-access=READ-WRITE, type=UInt8
    KeSMSuMdNum4s
      parameter data prototype Val: sw-calibration-access=READ-WRITE, type=UInt8
    KeSMSuMdNum6s7s
      parameter data prototype Val: sw-calibration-access=READ-WRITE, type=UInt8
    KeSMSuMdNums
      parameter data prototype Val: sw-calibration-access=READ-WRITE, type=UInt8
    KeSMSuRspStatHldTm
      parameter data prototype Val: sw-calibration-access=READ-WRITE, type=UInt8
    KeSMSuSRSMdSlctSwDurnTm
      parameter data prototype Val: sw-calibration-access=READ-WRITE, type=UInt8
    MdChime2Enable
      parameter data prototype Val: sw-calibration-access=READ-WRITE, type=Implementation/Boolean
    SRSconvertArray
      parameter data prototype Val: sw-calibration-access=READ-WRITE, type=Array1x32_Uint8
    SRSPosNumConfig
      parameter data prototype Val: sw-calibration-access=READ-WRITE, type=UInt8
package /PATAC/MSM/ModeAdjust/CompuMethods
  compu method MdRspLocal2: 0=MdRsp_None, 1=MdRsp_RecallSuccessfully, 2=MdRsp_RecallUnsuccessfully_LocalInterrupt, 3=MdRsp_RecallUnsuccessfully_NonEnghSpace, 4=MdRsp_RecallOngoing, 5=MdRsp_TargetPositionAlready, 6=MdRsp_LowPower, 7=MdRsp_CrashStat, 8=MdRsp_ThdRwOccupt, 9=MdRsp_PosNotLrn, 10=MdRsp_NotParkStat, 11=MdRsp_SpdNotCorrt
package /PATAC/MSM/ModeAdjust/DataType
  14 x impl type, all with sw-calibration-access=READ-ONLY, type-emitter=RTE:
    array1x32_Boolean: category=ARRAY
      element Element: array-size=32, array-size-semantics=FIXED-SIZE, implementation-data-type=Implementation/Boolean
    array1x32_SrcReqTp: category=ARRAY
      element Element: array-size=32, array-size-semantics=FIXED-SIZE, implementation-data-type=SrcReqTp1
    array1x32_Uint32: category=ARRAY
      element Element: array-size=32, array-size-semantics=FIXED-SIZE, implementation-data-type=UInt32
    Array1x32_Uint8: category=ARRAY
      element Element: array-size=32, array-size-semantics=FIXED-SIZE, implementation-data-type=UInt8
    EventSts1: category=VALUE, base-type=UInt8, compu {0=EventSts_NoAct, 1=EventSts_Act, 2=EventSts_CancleChime}
    MdRspLocal2: category=VALUE, base-type=UInt8, compu-method=MdRspLocal2
    MdTp1: category=VALUE, base-type=UInt8, compu {0=MdTp_None, 1=MdTp_EzeEntry, 2=MdTp_EzeExt, 3=MdTp_Vip, 4=MdTp_Lug, 5=MdTp_Recovery, 6=MdTp_Intimacy, 7=MdTp_Family, 8=MdTp_Lying, 9=MdTp_LgrstOpenLt, 10=MdTp_LgrstCloseLt, 11=MdTp_LgrstOpenRt, 12=MdTp_LgrstCloseRt}
    MdXX_QuitArray: category=ARRAY
      element Element: array-size=32, array-size-semantics=FIXED-SIZE, compu-method=MdRspLocal2, implementation-data-type=MdRspLocal2
    ModeList: category=ARRAY
      element Val: array-size=11, array-size-semantics=FIXED-SIZE, implementation-data-type=UInt8
    PowerMode1: category=VALUE, base-type=UInt8, compu {0=PowerMode_Off, 1=PowerMode_Acc, 2=PowerMode_Run, 3=PowerMode_Crank, 4=PowerMode_Invalid}
    SrcReqTp1: category=VALUE, base-type=UInt8, compu {0=SrcReqTp_None, 1=SrcReqTp_Local, 2=SrcReqTp_HMI2L, 3=SrcReqTp_HMI2R, 4=SrcReqTp_HMI, 5=SrcReqTp_Remote, 6=SrcReqTp_SRS}
    SRSCurMode2:
      category=VALUE
      base-type=UInt8
      compu {0=SRSMode_None, 1=SRSMode_EZEEntry, 2=SRSMode_EzeExt, 3=SRSMode_LfVip, 4=SRSMode_RtVip, 5=SRSMode_AllVip, 6=SRSMode_LfLug, 7=SRSMode_RtLug, 8=SRSMode_AllLug, 9=SRSMode_IntimacyL, 10=SRSMode_FamilyR, 11=SRSMode_FamilyL, 12=SRSMode_RcvyL, 13=SRSMode_RcvyR, 14=SRSMode_LyingL, 15=SRSMode_LyingR, 16=SRSMode_LgrstOpenLt, 17=SRSMode_LgrstCloseLt, 18=SRSMode_LgrstOpenRt, 19=SRSMode_LgrstCloseRt, 20=SRSMode_IntimacyR, 21=SRSMode_EzeEntry4s2L, 22=SRSMode_EzeExt4s2L, 23=SRSMode_EzeEntry4s2R, 24=SRSMode_EzeExt4s2R, 25=SRSMode_EzeEntryAll4sBwd, 26=SRSMode_EzeEntryAll4sFwd}
    SRSIndicatorStat: category=VALUE, base-type=UInt8, compu {0=SRSIndicatorStat_NoIndicator, 1=SRSIndicatorStat_Mode1On, 2=SRSIndicatorStat_Mode2On, 3=SRSIndicatorStat_Mode3On, 4=SRSIndicatorStat_Mode4On, 5=SRSIndicatorStat_Mode5On, 6=SRSIndicatorStat_Mode6On, 7=SRSIndicatorStat_Mode7On, 8=SRSIndicatorStat_Mode8On, 9=SRSIndicatorStat_Mode9On, 10=SRSIndicatorStat_Mode10On, 11..15=Reserved1..Reserved5}
    SRSSlctSwIndTyp: category=VALUE, base-type=UInt8, compu {0=IndicationOff, 1=FlashRate1, 2=FlashRate2, 3=Continuous}
package /PATAC/MSM/ModeAdjust/PortInterface
  25 x client server interface:
    CHM2ActiveReqChk
      operation Cal
    CHM2ActiveSubStateCtrl
      operation Cal
    CHM2Ctrl
      operation Cal
    CHM2StateCtrl
      operation Cal
    IsStBsy32
      operation Clear
        arg ClearBit: type=UInt32, direction=IN, server-argument-impl-policy=USE-ARGUMENT-TYPE
      operation Get
        arg IsStBsy32Bit: type=UInt32, direction=OUT, server-argument-impl-policy=USE-ARGUMENT-TYPE
      operation Set
        arg SetBit: type=UInt32, direction=IN, server-argument-impl-policy=USE-ARGUMENT-TYPE
    MdBsyClear4s
      operation Cal
    MdBsyClear6s7s
      operation Cal
    MdEnAndBsyChk
      operation Cal
        arg modestate32: type=UInt32, direction=OUT, server-argument-impl-policy=USE-ARGUMENT-TYPE
    MdEnChk
      operation Cal  # StNun: 0 :4s 1:6s 2:7s 3:4sp
    MdEnClear
      operation Cal
    MdSWReqChk
      operation Cal
        arg modestate32: type=UInt32, direction=IN, server-argument-impl-policy=USE-ARGUMENT-TYPE
    MdXX_QuitChk
      operation Cal
    MdXX_QuitReason
      operation Calc
        5 x arg, all with server-argument-impl-policy=USE-ARGUMENT-TYPE:
          MdDone: type=UInt8, direction=IN
          ExitCond: type=DataTypes/Boolean, direction=IN
          SWInt: type=DataTypes/Boolean, direction=IN
          SoftInt: type=DataTypes/Boolean, direction=IN
          MdQuitReason: type=MdRspLocal2, direction=OUT
    MdXX_RspOutCommCalc
      operation Cal
    MdXX_RspToNetWork
      operation Cal
    MdXX_Status
      operation Cal
    MdXX_StatusToNetWork
      operation Cal
    MdXXArray
      operation Cal
    ModeRsp
      operation Cal
    ModeState32Server
      operation Clear
        arg ClearBit: type=UInt32, direction=IN, server-argument-impl-policy=USE-ARGUMENT-TYPE
      operation Get
        arg MdEn32: type=UInt32, direction=OUT, server-argument-impl-policy=USE-ARGUMENT-TYPE
      operation Set
        arg SetBit: type=UInt32, direction=IN, server-argument-impl-policy=USE-ARGUMENT-TYPE
    ModeStateCtrl
      operation Cal
    SRSModeState
      operation Cal
    SRSSwIndCtrl
      operation Cal
    stateonoffchk
      operation Cal
        arg modestate32: type=UInt32, direction=IN, server-argument-impl-policy=USE-ARGUMENT-TYPE
        arg modestateon: type=Implementation/Boolean, direction=OUT, server-argument-impl-policy=USE-ARGUMENT-TYPE
    StPassCmprtMdHMIDisCmdCalc
      operation Cal
  48 x sender receiver interface:
    AnyModeAjust: invalidation-policy{data-element=AnyModeAjust/Val, handle-invalid=DONT-INVALIDATE}
      data Val: type=Implementation/Boolean
    ChkBsyBitArray: invalidation-policy{data-element=ChkBsyBitArray/Val, handle-invalid=DONT-INVALIDATE}
      data Val: type=array1x32_Uint32
    CHM2ActiveReq: invalidation-policy{data-element=CHM2ActiveReq/Val, handle-invalid=DONT-INVALIDATE}
      data Val: type=Implementation/Boolean
    CHM2ActiveSubState: invalidation-policy{data-element=CHM2ActiveSubState/Val, handle-invalid=DONT-INVALIDATE}
      data Val: type=Implementation/Boolean
    ChmEvenState: invalidation-policy{data-element=ChmEvenState/Val, handle-invalid=DONT-INVALIDATE}
      data Val: type=EventSts1
    CommCond: invalidation-policy{data-element=CommCond/Val, handle-invalid=DONT-INVALIDATE}
      data Val: type=Implementation/Boolean
    CommExitCond: invalidation-policy{data-element=CommExitCond/Val, handle-invalid=DONT-INVALIDATE}
      data Val: type=Implementation/Boolean
    CommExitCondwithSpeed: invalidation-policy{data-element=CommExitCondwithSpeed/Val, handle-invalid=DONT-INVALIDATE}
      data Val: type=Implementation/Boolean
    HMI2LMdRsp: invalidation-policy{data-element=HMI2LMdRsp/Val, handle-invalid=DONT-INVALIDATE}
      data Val: type=UInt8
    HMI2RMdRsp: invalidation-policy{data-element=HMI2RMdRsp/Val, handle-invalid=DONT-INVALIDATE}
      data Val: type=UInt8
    IfVeSMSuChmMgrStat: invalidation-policy{data-element=IfVeSMSuChmMgrStat/Val, handle-invalid=DONT-INVALIDATE}
      data Val: type=UInt16
    IntEnable: invalidation-policy{data-element=IntEnable/Val, handle-invalid=DONT-INVALIDATE}
      data Val: type=IntEnable
    IsStBsy32Bit: invalidation-policy{data-element=IsStBsy32Bit/Val, handle-invalid=DONT-INVALIDATE}
      data Val: type=UInt32
    IsTargetPos32Bit: invalidation-policy{data-element=IsTargetPos32Bit/Val, handle-invalid=DONT-INVALIDATE}
      data Val: type=UInt32
    MdRclRspStat: invalidation-policy{data-element=MdRclRspStat/Val, handle-invalid=DONT-INVALIDATE}
      data Val: type=UInt8
    MdReq: invalidation-policy{data-element=MdReq/Val, handle-invalid=DONT-INVALIDATE}
      data Val: type=Implementation/Boolean
    MdReqArray: invalidation-policy{data-element=MdReqArray/Val, handle-invalid=DONT-INVALIDATE}
      data Val: type=array1x32_Boolean
    MdSWIntSrc_R: invalidation-policy{data-element=MdSWIntSrc_R/Val, handle-invalid=DONT-INVALIDATE}  # bit0-acsext bit1-acsentry bit2-ltvip bit3-Rtvip bit4-lug bit5-ltrcvy bit6-rtrcvy
      data Val: type=UInt16
    MdXX_CommExitArray: invalidation-policy{data-element=MdXX_CommExitArray/Val, handle-invalid=DONT-INVALIDATE}
      data Val: type=array1x32_Boolean
    MdXX_MdDoneArray: invalidation-policy{data-element=MdXX_MdDoneArray/Val, handle-invalid=DONT-INVALIDATE}
      data Val: type=Array1x32_Uint8
    MdXX_Quit32bit: invalidation-policy{data-element=MdXX_Quit32bit/Val, handle-invalid=DONT-INVALIDATE}
      data Val: type=UInt32
    MdXX_QuitArray: invalidation-policy{data-element=MdXX_QuitArray/Val, handle-invalid=DONT-INVALIDATE}
      data Val: type=MdXX_QuitArray
    MdXX_RspOutComm
      32 x data, all with type=UInt8:
        Md1_RspOutComm
        Md{10..19}_RspOutComm
        Md2_RspOutComm
        Md{20..29}_RspOutComm
        Md3_RspOutComm
        Md{30..32}_RspOutComm
        Md{4..9}_RspOutComm
      invalidation-policys:
        data-element=Md1_RspOutComm, handle-invalid=DONT-INVALIDATE
        data-element=Md11_RspOutComm, handle-invalid=DONT-INVALIDATE
        data-element=Md12_RspOutComm, handle-invalid=DONT-INVALIDATE
        data-element=Md14_RspOutComm, handle-invalid=DONT-INVALIDATE
        data-element=Md13_RspOutComm, handle-invalid=DONT-INVALIDATE
        data-element=Md19_RspOutComm, handle-invalid=DONT-INVALIDATE
        data-element=Md15_RspOutComm, handle-invalid=DONT-INVALIDATE
        data-element=Md18_RspOutComm, handle-invalid=DONT-INVALIDATE
        data-element=Md16_RspOutComm, handle-invalid=DONT-INVALIDATE
        data-element=Md17_RspOutComm, handle-invalid=DONT-INVALIDATE
        data-element=Md2_RspOutComm, handle-invalid=DONT-INVALIDATE
        data-element=Md21_RspOutComm, handle-invalid=DONT-INVALIDATE
        data-element=Md22_RspOutComm, handle-invalid=DONT-INVALIDATE
        data-element=Md24_RspOutComm, handle-invalid=DONT-INVALIDATE
        data-element=Md23_RspOutComm, handle-invalid=DONT-INVALIDATE
        data-element=Md{25..27}_RspOutComm, handle-invalid=DONT-INVALIDATE
        data-element=Md29_RspOutComm, handle-invalid=DONT-INVALIDATE
        data-element=Md28_RspOutComm, handle-invalid=DONT-INVALIDATE
        data-element=Md3_RspOutComm, handle-invalid=DONT-INVALIDATE
        data-element=Md31_RspOutComm, handle-invalid=DONT-INVALIDATE
        data-element=Md32_RspOutComm, handle-invalid=DONT-INVALIDATE
        data-element=Md{4..6}_RspOutComm, handle-invalid=DONT-INVALIDATE
        data-element=Md9_RspOutComm, handle-invalid=DONT-INVALIDATE
        data-element=Md7_RspOutComm, handle-invalid=DONT-INVALIDATE
        data-element=Md8_RspOutComm, handle-invalid=DONT-INVALIDATE
        data-element=Md10_RspOutComm, handle-invalid=DONT-INVALIDATE
        data-element=Md20_RspOutComm, handle-invalid=DONT-INVALIDATE
        data-element=Md30_RspOutComm, handle-invalid=DONT-INVALIDATE
    MdXX_SoftIntArray: invalidation-policy{data-element=MdXX_SoftIntArray/Val, handle-invalid=DONT-INVALIDATE}
      data Val: type=array1x32_Boolean
    MdXX_SrcReqTp
      32 x data, all with type=SrcReqTp1:
        Md1_SrcTp
        Md{10..19}_SrcTp
        Md2_SrcTp
        Md{20..29}_SrcTp
        Md3_SrcTp
        Md{30..32}_SrcTp
        Md{4..9}_SrcTp
      invalidation-policys:
        data-element=Md1_SrcTp, handle-invalid=DONT-INVALIDATE
        data-element=Md2_SrcTp, handle-invalid=DONT-INVALIDATE
        data-element=Md4_SrcTp, handle-invalid=DONT-INVALIDATE
        data-element=Md3_SrcTp, handle-invalid=DONT-INVALIDATE
        data-element=Md6_SrcTp, handle-invalid=DONT-INVALIDATE
        data-element=Md5_SrcTp, handle-invalid=DONT-INVALIDATE
        data-element=Md10_SrcTp, handle-invalid=DONT-INVALIDATE
        data-element=Md7_SrcTp, handle-invalid=DONT-INVALIDATE
        data-element=Md12_SrcTp, handle-invalid=DONT-INVALIDATE
        data-element=Md8_SrcTp, handle-invalid=DONT-INVALIDATE
        data-element=Md11_SrcTp, handle-invalid=DONT-INVALIDATE
        data-element=Md9_SrcTp, handle-invalid=DONT-INVALIDATE
        data-element=Md14_SrcTp, handle-invalid=DONT-INVALIDATE
        data-element=Md13_SrcTp, handle-invalid=DONT-INVALIDATE
        data-element=Md17_SrcTp, handle-invalid=DONT-INVALIDATE
        data-element=Md16_SrcTp, handle-invalid=DONT-INVALIDATE
        data-element=Md15_SrcTp, handle-invalid=DONT-INVALIDATE
        data-element=Md19_SrcTp, handle-invalid=DONT-INVALIDATE
        data-element=Md18_SrcTp, handle-invalid=DONT-INVALIDATE
        data-element=Md{20..22}_SrcTp, handle-invalid=DONT-INVALIDATE
        data-element=Md24_SrcTp, handle-invalid=DONT-INVALIDATE
        data-element=Md23_SrcTp, handle-invalid=DONT-INVALIDATE
        data-element=Md26_SrcTp, handle-invalid=DONT-INVALIDATE
        data-element=Md25_SrcTp, handle-invalid=DONT-INVALIDATE
        data-element=Md28_SrcTp, handle-invalid=DONT-INVALIDATE
        data-element=Md27_SrcTp, handle-invalid=DONT-INVALIDATE
        data-element=Md30_SrcTp, handle-invalid=DONT-INVALIDATE
        data-element=Md29_SrcTp, handle-invalid=DONT-INVALIDATE
        data-element=Md32_SrcTp, handle-invalid=DONT-INVALIDATE
        data-element=Md31_SrcTp, handle-invalid=DONT-INVALIDATE
    MdXX_SrcReqTpArray: invalidation-policy{data-element=MdXX_SrcReqTpArray/Val, handle-invalid=DONT-INVALIDATE}
      data Val: type=array1x32_SrcReqTp
    MdXX_Stat
      32 x data, all with type=UInt8:
        Md1_Stat
        Md{10..19}_Stat
        Md2_Stat
        Md{20..29}_Stat
        Md3_Stat
        Md{30..32}_Stat
        Md{4..9}_Stat
      invalidation-policys:
        data-element=Md{1..3}_Stat, handle-invalid=DONT-INVALIDATE
        data-element=Md5_Stat, handle-invalid=DONT-INVALIDATE
        data-element=Md4_Stat, handle-invalid=DONT-INVALIDATE
        data-element=Md12_Stat, handle-invalid=DONT-INVALIDATE
        data-element=Md6_Stat, handle-invalid=DONT-INVALIDATE
        data-element=Md15_Stat, handle-invalid=DONT-INVALIDATE
        data-element=Md7_Stat, handle-invalid=DONT-INVALIDATE
        data-element=Md13_Stat, handle-invalid=DONT-INVALIDATE
        data-element=Md8_Stat, handle-invalid=DONT-INVALIDATE
        data-element=Md18_Stat, handle-invalid=DONT-INVALIDATE
        data-element=Md9_Stat, handle-invalid=DONT-INVALIDATE
        data-element=Md14_Stat, handle-invalid=DONT-INVALIDATE
        data-element=Md10_Stat, handle-invalid=DONT-INVALIDATE
        data-element=Md16_Stat, handle-invalid=DONT-INVALIDATE
        data-element=Md11_Stat, handle-invalid=DONT-INVALIDATE
        data-element=Md20_Stat, handle-invalid=DONT-INVALIDATE
        data-element=Md17_Stat, handle-invalid=DONT-INVALIDATE
        data-element=Md19_Stat, handle-invalid=DONT-INVALIDATE
        data-element=Md22_Stat, handle-invalid=DONT-INVALIDATE
        data-element=Md21_Stat, handle-invalid=DONT-INVALIDATE
        data-element=Md24_Stat, handle-invalid=DONT-INVALIDATE
        data-element=Md23_Stat, handle-invalid=DONT-INVALIDATE
        data-element=Md26_Stat, handle-invalid=DONT-INVALIDATE
        data-element=Md25_Stat, handle-invalid=DONT-INVALIDATE
        data-element=Md28_Stat, handle-invalid=DONT-INVALIDATE
        data-element=Md27_Stat, handle-invalid=DONT-INVALIDATE
        data-element=Md30_Stat, handle-invalid=DONT-INVALIDATE
        data-element=Md29_Stat, handle-invalid=DONT-INVALIDATE
        data-element=Md32_Stat, handle-invalid=DONT-INVALIDATE
        data-element=Md31_Stat, handle-invalid=DONT-INVALIDATE
    MdXX_SWIntArray: invalidation-policy{data-element=MdXX_SWIntArray/Val, handle-invalid=DONT-INVALIDATE}
      data Val: type=array1x32_Boolean
    ModeAdjustAvailable: invalidation-policy{data-element=ModeAdjustAvailable/Val, handle-invalid=DONT-INVALIDATE}
      data Val: type=Implementation/Boolean
    ModeSrcTp: invalidation-policy{data-element=ModeSrcTp/Val, handle-invalid=DONT-INVALIDATE}
      data Val: type=SrcReqTp1
    ModeState: invalidation-policy{data-element=ModeState/Val, handle-invalid=DONT-INVALIDATE}
      data Val: type=MdTp1
    modestate32: invalidation-policy{data-element=modestate32/Val, handle-invalid=DONT-INVALIDATE}
      data Val: type=UInt32
    PercPos: invalidation-policy{data-element=PercPos/Val, handle-invalid=DONT-INVALIDATE}
      data Val: type=UInt16
    PosArray: invalidation-policy{data-element=PosArray/Val, handle-invalid=DONT-INVALIDATE}
      data Val: type=ModeList
    PowerMode: invalidation-policy{data-element=PowerMode/Val, handle-invalid=DONT-INVALIDATE}
      data Val: type=PowerMode1
    SetBsyBitArray: invalidation-policy{data-element=SetBsyBitArray/Val, handle-invalid=DONT-INVALIDATE}
      data Val: type=array1x32_Uint32
    SetEnBitArray: invalidation-policy{data-element=SetEnBitArray/Val, handle-invalid=DONT-INVALIDATE}
      data Val: type=array1x32_Uint32
    SRSCrtMdIndTyp_67_2: invalidation-policy{data-element=SRSCrtMdIndTyp_67_2/Val, handle-invalid=DONT-INVALIDATE}
      data Val: type=UInt8
    SRSCrtMdStat_67_2: invalidation-policy{data-element=SRSCrtMdStat_67_2/Val, handle-invalid=DONT-INVALIDATE}
      data Val: type=UInt8
    SRSCurMode: invalidation-policy{data-element=SRSCurMode/Val, handle-invalid=DONT-INVALIDATE}
      data Val: type=SRSCurMode2
    SRSCurMode2: invalidation-policy{data-element=SRSCurMode2/Val, handle-invalid=DONT-INVALIDATE}
      data Val: type=SRSCurMode2
    SRSMdSlctSwIndTyp_67_2: invalidation-policy{data-element=SRSMdSlctSwIndTyp_67_2/Val, handle-invalid=DONT-INVALIDATE}
      data Val: type=SRSSlctSwIndTyp
    SRSMdSlctSwStat_67_2: invalidation-policy{data-element=SRSMdSlctSwStat_67_2/Val, handle-invalid=DONT-INVALIDATE}
      data Val: type=SRSIndicatorStat
    StNumFlg
      4 x data, all with type=Implementation/Boolean:
        Is4s
        Is6s
        Is6s7s
        Is7s
      invalidation-policys:
        data-element=Is7s, handle-invalid=DONT-INVALIDATE
        data-element=Is6s, handle-invalid=DONT-INVALIDATE
        data-element=Is4s, handle-invalid=DONT-INVALIDATE
        data-element=Is6s7s, handle-invalid=DONT-INVALIDATE
    StPassCmprtMdCrtMdStat: invalidation-policy{data-element=StPassCmprtMdCrtMdStat/Val, handle-invalid=DONT-INVALIDATE}
      data Val: type=UInt8
    StPassCmprtMdHMIDisCmdSrv: invalidation-policy{data-element=StPassCmprtMdHMIDisCmdSrv/Val, handle-invalid=DONT-INVALIDATE}
      data Val: type=UInt8
    StSrvMdRsp: invalidation-policy{data-element=StSrvMdRsp/Val, handle-invalid=DONT-INVALIDATE}
      data Val: type=UInt8
    VeSMSuMdNum: invalidation-policy{data-element=VeSMSuMdNum/Val, handle-invalid=DONT-INVALIDATE}
      data Val: type=UInt8
package /PATAC/MSM/PortInterfaces
  parameter interface KeSMSuChmReqDurnTm
    parameter data prototype Val: sw-calibration-access=READ-WRITE, type=UInt8
  parameter interface KeSMSuChmReqIntlTm
    parameter data prototype Val: sw-calibration-access=READ-WRITE, type=UInt8
  sender receiver interface IfVeSMSuSecRwLtStFrwdBkwdPos: invalidation-policy{data-element=IfVeSMSuSecRwLtStFrwdBkwdPos/Val, handle-invalid=DONT-INVALIDATE}
    data Val: type=UInt16
